VERSION ""

NS_ :

BS_:

BU_: bms car_control charger

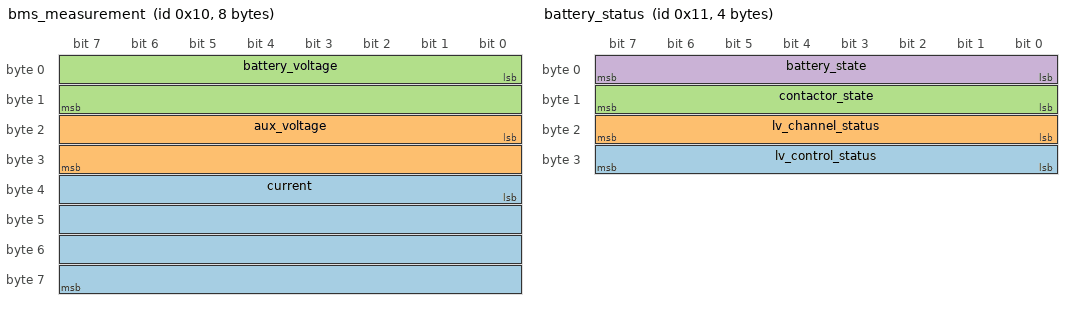
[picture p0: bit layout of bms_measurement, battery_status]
BO_ 16 bms_measurement: 8 bms
 SG_ current : 32|32@1+ (1.0,0) [0|0] "A" Vector__XXX
 SG_ aux_voltage : 16|16@1+ (0.001,0) [0|0] "V" Vector__XXX
 SG_ battery_voltage : 0|16@1+ (0.01,0) [0|0] "V" Vector__XXX

BO_ 17 battery_status: 4 bms
 SG_ lv_control_status : 24|8@1+ (1,0) [0|0] "" Vector__XXX
 SG_ lv_channel_status : 16|8@1+ (1,0) [0|0] "" Vector__XXX
 SG_ contactor_state : 8|8@1+ (1,0) [0|0] "" Vector__XXX
 SG_ battery_state : 0|8@1+ (1,0) [0|0] "" Vector__XXX

BO_ 18 bms_kill_reason: 8 bms
 SG_ reason2 : 8|8@1+ (1,0) [0|0] "" Vector__XXX
 SG_ reason1 : 0|8@1+ (1,0) [0|0] "" Vector__XXX

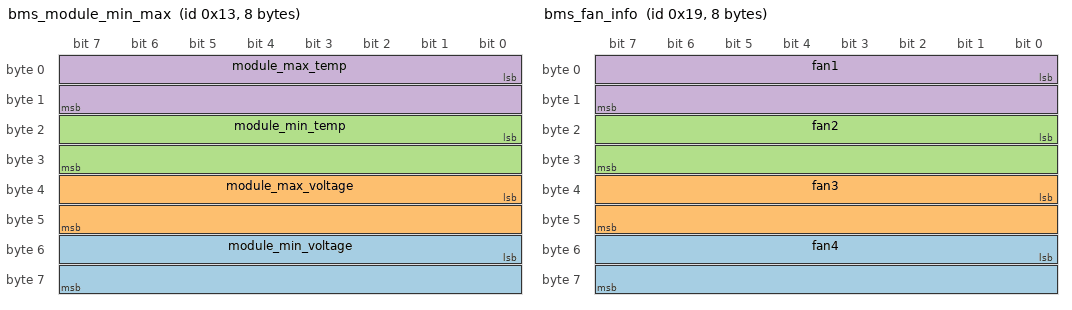
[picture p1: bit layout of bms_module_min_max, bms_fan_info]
BO_ 19 bms_module_min_max: 8 bms
 SG_ module_min_voltage : 48|16@1+ (0.001,0) [0|0] "V"  car_control,charger
 SG_ module_max_voltage : 32|16@1+ (0.001,0) [0|0] "V"  car_control,charger
 SG_ module_min_temp : 16|16@1- (0.01,0) [0|0] "C"  car_control,charger
 SG_ module_max_temp : 0|16@1- (0.01,0) [0|0] "C"  car_control,charger

BO_ 20 bms_soc: 4 bms
 SG_ soc : 0|32@1+ (1,0) [0|0] "" Vector__XXX

BO_ 21 bms_capacity: 8 bms
 SG_ wh : 32|32@1+ (1,0) [0|0] "Wh" Vector__XXX
 SG_ ah : 0|32@1+ (1,0) [0|0] "Ah" Vector__XXX

BO_ 24 bms_currentlimit: 4 bms
 SG_ current_min : 16|16@1+ (0.01,0) [0|0] "A" Vector__XXX
 SG_ current_max : 0|16@1+ (0.01,0) [0|0] "A" Vector__XXX

BO_ 25 bms_fan_info: 8 Vector__XXX
 SG_ fan4 : 48|16@1+ (1,0) [0|0] "RPM" Vector__XXX
 SG_ fan3 : 32|16@1+ (1,0) [0|0] "RPM" Vector__XXX
 SG_ fan2 : 16|16@1+ (1,0) [0|0] "RPM" Vector__XXX
 SG_ fan1 : 0|16@1+ (1,0) [0|0] "RPM" Vector__XXX

BO_ 27 bms_set_min_fan_speed: 8 bms
 SG_ temperature : 32|32@1+ (1,0) [0|0] "C" Vector__XXX
 SG_ voltage : 0|32@1+ (1,0) [0|0] "V" Vector__XXX

BO_ 117 bms_charger_response: 1 bms
 SG_ charging_ready : 0|1@1+ (1,0) [0|0] ""  charger

BA_DEF_ BO_  "GenMsgCycleTime" INT 0 65535;
BA_DEF_DEF_  "GenMsgCycleTime" 0;
BA_ "GenMsgCycleTime" BO_ 16 500;
BA_ "GenMsgCycleTime" BO_ 17 500;
BA_ "GenMsgCycleTime" BO_ 18 500;
BA_ "GenMsgCycleTime" BO_ 19 500;
BA_ "GenMsgCycleTime" BO_ 20 500;
BA_ "GenMsgCycleTime" BO_ 21 500;
BA_ "GenMsgCycleTime" BO_ 24 500;
BA_ "GenMsgCycleTime" BO_ 27 500;
BA_ "GenMsgCycleTime" BO_ 117 500;
VAL_ 17 lv_control_status 0 "aux_vicor_enable" 1 "bat_vicor_enable" 2 "aux_relay_held" 3 "aux_ref_enable" 4 "aux_charging_enable" 5 "kill_hv" 6 "kill_lv" 7 "start_button" ;
VAL_ 17 lv_channel_status 0 "aux_fault" 1 "main_fault" 2 "aux_power_valid" 3 "main_power_valid" 4 "aux_power_active" 5 "main_power_active" ;
VAL_ 17 contactor_state 0 "BATTERY_HIGH_CONTRACTOR" 1 "BATTERY_LOW_CONTACTOR" 2 "BATTERY_VICOR_CONTACTOR" 3 "BATTERY_PRE_CONTACTOR" 4 "BATTERY_HIGH2_CONTACTOR" 5 "BATTERY_LOW2_CONTACTOR" 6 "CHARGER_HIGH_CONTACTOR" 7 "CHARGER_PRE_CONTACTOR" ;
VAL_ 17 battery_state 0 "STARTUP" 1 "PRECHARGE" 2 "DISCHARGING" 3 "LV_ONLY" 4 "CHARGING" 5 "WALL_CHARGING" 6 "KILLED" ;
VAL_ 18 reason2 0 "NONE" 1 "HARDWARE" 2 "KILL_PACKET" 3 "UNKNOWN" 4 "OVERCURRENT" 5 "PRECHARGE_FAIL" 6 "AUX_OVER_UNDER" ;
VAL_ 18 reason1 0 "NONE" 1 "OvERVOLT" 2 "UNDERVOLT" 3 "OVERTEMP" 4 "TEMP_DISCONNECT" 5 "COMM_FAIL" ;
SIG_VALTYPE_ 16 current : 1;
SIG_VALTYPE_ 20 soc : 1;
SIG_VALTYPE_ 21 ah : 1;
SIG_VALTYPE_ 21 wh : 1;
SIG_VALTYPE_ 27 voltage : 1;
SIG_VALTYPE_ 27 temperature : 1;
